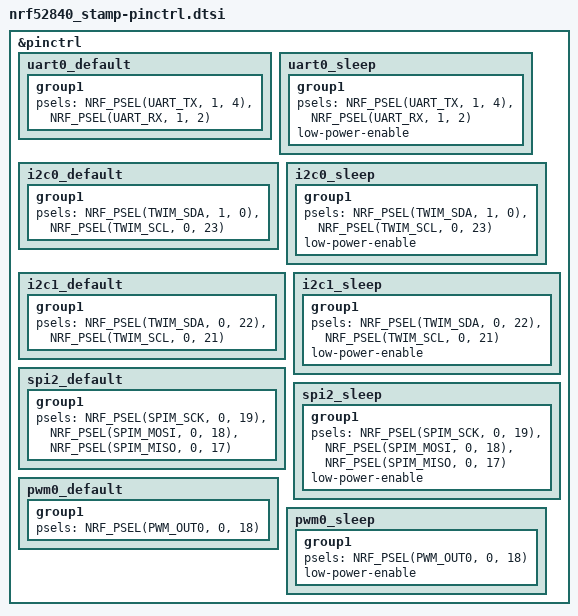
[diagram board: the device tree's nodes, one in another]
/*
 * Copyright (c) 2026 Icy Electronics
 * SPDX-License-Identifier: Apache-2.0
 */

&pinctrl {
	uart0_default: uart0_default {
		group1 {
			psels = <NRF_PSEL(UART_TX, 1, 4)>,
				<NRF_PSEL(UART_RX, 1, 2)>;
		};
	};

	uart0_sleep: uart0_sleep {
		group1 {
			psels = <NRF_PSEL(UART_TX, 1, 4)>,
				<NRF_PSEL(UART_RX, 1, 2)>;
			low-power-enable;
		};
	};

	i2c0_default: i2c0_default {
		group1 {
			psels = <NRF_PSEL(TWIM_SDA, 1, 0)>,
				<NRF_PSEL(TWIM_SCL, 0, 23)>;
		};
	};

	i2c0_sleep: i2c0_sleep {
		group1 {
			psels = <NRF_PSEL(TWIM_SDA, 1, 0)>,
				<NRF_PSEL(TWIM_SCL, 0, 23)>;
			low-power-enable;
		};
	};

	i2c1_default: i2c1_default {
		group1 {
			psels = <NRF_PSEL(TWIM_SDA, 0, 22)>,
				<NRF_PSEL(TWIM_SCL, 0, 21)>;
		};
	};

	i2c1_sleep: i2c1_sleep {
		group1 {
			psels = <NRF_PSEL(TWIM_SDA, 0, 22)>,
				<NRF_PSEL(TWIM_SCL, 0, 21)>;
			low-power-enable;
		};
	};

	spi2_default: spi2_default {
		group1 {
			psels = <NRF_PSEL(SPIM_SCK, 0, 19)>,
				<NRF_PSEL(SPIM_MOSI, 0, 18)>,
				<NRF_PSEL(SPIM_MISO, 0, 17)>;
		};
	};

	spi2_sleep: spi2_sleep {
		group1 {
			psels = <NRF_PSEL(SPIM_SCK, 0, 19)>,
				<NRF_PSEL(SPIM_MOSI, 0, 18)>,
				<NRF_PSEL(SPIM_MISO, 0, 17)>;
			low-power-enable;
		};
	};

	pwm0_default: pwm0_default {
		group1 {
			psels = <NRF_PSEL(PWM_OUT0, 0, 18)>;
		};
	};

	pwm0_sleep: pwm0_sleep {
		group1 {
			psels = <NRF_PSEL(PWM_OUT0, 0, 18)>;
			low-power-enable;
		};
	};
};
